# psoc4hvpaspm10 register map
Vendor: Infineon Technologies; Series: PSOC4HVPASPM10; File version: 1.0
CPU: CM0PLUS r0p1, little endian, MPU, no FPU, VTOR, 2 interrupt priority bits, 32 interrupts
Registers are 32-bit, read-write, reset 0x0 unless marked. A register's access mark holds for its fields unless they carry their own. Offsets are from the block's base; [hi:lo] are bit positions; lines under a group give offsets from that group; 'fields as' and 'values as' point back to an identical list; <NAME> marks a mode.

## SRSSHV — System Resources High Voltage Subsystem
Base 0x40030000
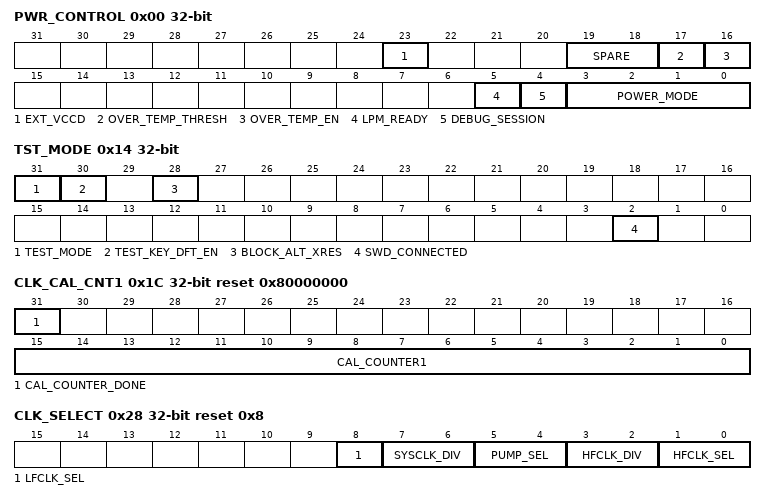
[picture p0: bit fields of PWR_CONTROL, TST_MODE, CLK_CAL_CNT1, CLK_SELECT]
0x00 PWR_CONTROL — Power Mode Control (Lock Protected)
  [23] EXT_VCCD — Always write 0 except as noted below. PSoC4-S0 and Streetfighter CapSense products may set this bit if Vccd is provided externally (on Vccd pin). Setting this bit turns off the active regulator and will lead to system reset (BOD) unless both Vddd and Vccd pins are supplied externally. This register field reset with hard reset (power related, XRES, WDT).
  [19:18] SPARE ro — Spare AHB readback bits that are hooked to PWR_PWRSYS_TRIM1.SPARE_TRIM[1:0] through spare logic equivalent to bitwise inversion. Engineering only, should always be set to default.
  [17] OVER_TEMP_THRESH — Over-temperature threshold. 0: TEMP_HIGH condition occurs between 110C and 145C. 1: TEMP_HIGH condition occurs between 50C and 90C (used for testing).
  [16] OVER_TEMP_EN — Enables the die over temperature sensor. Must be enabled when using the TEMP_HIGH interrupt.
  [5] LPM_READY ro — Indicates whether the low power mode regulator is ready to enter DeepSleep mode. 0: If DeepSleep mode is requested, device will enter SLEEP mode. When low power regulators are ready, device will automatically enter the originally requested mode. 1: Normal operation. DeepSleep works as described.
  [4] DEBUG_SESSION ro — Indicates whether a debug session is active (CDBGPWRUPREQ signal is 1)
    0=NO_SESSION (No debug session active); 1=SESSION_ACTIVE (Debug session is active)
  [3:0] POWER_MODE ro — Current power mode of the device. Note that this field cannot be read in all power modes on actual silicon.
    0=RESET (RESET state); 1=ACTIVE (ACTIVE state); 2=SLEEP (SLEEP state); 3=DEEP_SLEEP (DEEP_SLEEP state)
0x04 PWR_KEY_DELAY reset 0xF8 — Power System Key&Delay Register (Lock Protected)
  [9:0] WAKEUP_HOLDOFF — Delay to wait for references to settle on wakeup from DeepSleep. BOD is ignored and system does not resume until this delay expires. Note that the same delay on POR is hard-coded. The default assumes the output of the predivider is 48MHz + 3 percent. Firmware may scale this setting according to the fastest actual clock frequency that can occur when waking from DeepSleep.
0x14 TST_MODE — Test Mode Control Register
  [31] TEST_MODE
  [30] TEST_KEY_DFT_EN ro
  [28] BLOCK_ALT_XRES — Relevant only for parts that have the alternate XRES mechanism of overloading a GPIO pin temporarily as alternate XRES during test. When set, this bit blocks the alternate XRES function, such that the pin can be used for normal I/O or for ddft/adft observation. This register field resets with hard reset (power related, XRES, WDT)
  [2] SWD_CONNECTED ro
0x1C CLK_CAL_CNT1 reset 0x80000000 — Clock Calibration Counter 1
  [31] CAL_COUNTER_DONE ro — Status bit indicating that the internal counter #1 is finished counting and CLK_CAL_CNT2.COUNTER stopped counting up
  [15:0] CAL_COUNTER1 — Down-counter clocked on DFT output #0 (see CLK_DFT_SELECT). This register always reads as zero. Counting starts internally when this register is written with a nonzero value. CAL_COUNTER_DONE goes immediately low to indicate that the counter has started and will be asserted when the counters are done. Do not write this field unless CAL_COUNTER_DONE==1. Both clocks must be running or the measurement will not complete. A stalled counter can be recovered by selecting valid clocks, waiting until the measurement completes, and discarding the first result. CAL_COUNTER1 should always be > 1. Due to internal clock synchronization CAL_COUNTER1 should be at least 5 times the 1/F_cnt2.
0x20 CLK_CAL_CNT2 ro — Clock Calibration Counter 2
  [15:0] CAL_COUNTER2 — Up-counter clocked on DFT output #1 (see CLK_DFT_SELECT). When CLK_CAL_CNT1.CAL_COUNTER_DONE==1, the counter is stopped and can be read by SW. Do not read this value unless CAL_COUNTER_DONE==1. The expected final value is related to the ratio of clock frequencies used for the two counters and the value loaded into counter 1: CLK_CAL_CNT2.CAL_COUNTER2=(F_cnt2/F_cnt1)*(CLK_CAL_CNT1.CAL_COUNTER1)
0x28 CLK_SELECT reset 0x8 — Clock Select Register (Lock Protected)
  [8] LFCLK_SEL — Low Frequency Clock Select. Selecting a clock source that is not enabled will result in undefined behavior. If a clock source is disabled while selected, then the clock merely stops to all sources that receive it. In such a scenario, the disabled clock must be re-enabled, prior to switching FROM this clock source. Writes to this field are ignored unless the WDT is unlocked using WDT_LOCK register. It takes about 3 cycles of the new selected clock to switch away from the old clock to the new clock. Do not disable the original clock during this time. This register field resets with hard reset (power related, XRES, WDT).
    0=ILO (ILO - Internal Low Frequency Oscillator); 1=PILO (PILO - Precision Internal Low Frequency Oscillator. Only if PILO_PRESENT=1)
  [7:6] SYSCLK_DIV — Select clk_sys prescaler value.
    0=NO_DIV (clk_sys= clk_hf/1); 1=DIV_BY_2 (clk_sys= clk_hf/2); 2=DIV_BY_4 (clk_sys= clk_hf/4); 3=DIV_BY_8 (clk_sys= clk_hf/8)
  [5:4] PUMP_SEL — Selects clock source for charge pump clock. This clock is not guaranteed to be glitch free when changing any of its sources or settings.
    0=GND (No clock, connect to gnd); 1=IMO (Use main IMO output); 2=HFCLK (Use clk_hf (using selected source after predivider but before prescaler))
  [3:2] HFCLK_DIV — Selects clk_hf predivider value. It will take 3-4 clock cycles to switch to the new predivder value
    0=NO_DIV (Transparent mode, feed through selected clock source w/o dividing.); 1=DIV_BY_2 (Divide selected clock source by 2); 2=DIV_BY_4 (Divide selected clock source by 4); 3=DIV_BY_8 (Divide selected clock source by 8)
  [1:0] HFCLK_SEL — Selects a source for clk_hf and dsi_in[0]. Note that not all products support all clock sources. Selecting a clock source that is not supported or enabled will result in undefined behavior. It takes about 3 cycles of the new selected clock to switch away from the old clock to the new clock. Do not disable the original clock during this time.
    0=IMO (IMO - Internal R/C Oscillator); 1=EXTCLK (EXTCLK - External Clock Pin); 2=ECO (ECO - External-Crystal Oscillator or PLL subsystem output); 3=HPOSC (HPOSC - High Precision Oscillator. Only if HPOSC_PRESENT=1)
0x2C CLK_ILO_CONFIG reset 0x80000000 — ILO Configuration (Lock Protected)
  [31] ENABLE — Master enable for ILO oscillator. Clearing this bit will disable the ILO. Do not disable this clock if the CLK_LF uses it clock the source. Writes to this field are ignored when LFCLK_SEL is using this clock as the source and WDT is locked using WDT_LOCK register. This register resets when there is power related reset POR/XRES/BOD/OVD/WDT
0x30 CLK_IMO_CONFIG reset 0x80000000 — IMO Configuration (Lock Protected)
  [31] ENABLE — Master enable for IMO oscillator. Clearing this bit will disable the IMO. Don't do this if the system is running off it.
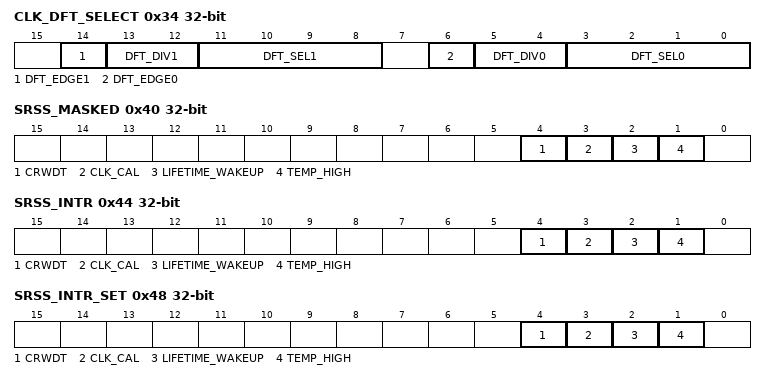
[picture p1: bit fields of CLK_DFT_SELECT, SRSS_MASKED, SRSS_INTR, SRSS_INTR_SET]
0x34 CLK_DFT_SELECT — Clock DFT Mode Selection Register
  [14] DFT_EDGE1 — Edge sensitivity for pre-divider (only relevant when DIV0>0).
    0=POSEDGE (Use posedge for divider); 1=NEGEDGE (Use negedge for divider)
  [13:12] DFT_DIV1 — Calibration Counter #2 pre-divider
    0=NO_DIV (Direct Output); 1=DIV_BY_2 (Divide by 2); 2=DIV_BY_4 (Divide by 4); 3=DIV_BY_8 (Divide by 8)
  [11:8] DFT_SEL1 — Select clock for Calibration Counter #2
    0=NC (Disabled - output is 0); 1=ILO (clk_ilo: ILO output); 2=IMO (clk_imo: IMO primary output); 3=ECO (clk_eco: ECO output); 4=EXTCLK (clk_ext: external clock input); 5=HFCLK (clk_hf: root of the high-speed clock tree); 6=LFCLK (clk_lf: root of the low-speed clock tree); 7=SYSCLK (clk_sys: root of the CPU/AHB clock tree (gated version of clk_hf)); 8=PUMPCLK (clk_pump: clock provided to charge pumps in FLASH and PA); 9=SLPCTRLCLK (clk_slpctrl: clock provided to Sleep Controller); 10=HPOSC (clk_hposc: HPOSC output. Applicable only if HPOSC_PRESENT=1); 11=PILO (clk_pilo: PILO output. Applicable only if PILO_PRESENT=1); 12=ILO_EN (clk_ilo: enable. Use for startup time measurements. Use only with DFT_DIV0.NO_DIV); 13=IMO_EN (clk_imo: enable. Use for startup time measurements. Use only with DFT_DIV0.NO_DIV); 14=HPOSC_EN (clk_hposc: enable. If HPOSC_PRESENT=1, Use for startup time measurements. Use only with DFT_DIV0.NO_DIV); 15=PILO_EN (clk_pilo: enable. If PILO_PRESENT=1, Use for startup time measurements. Use only with DFT_DIV0.NO_DIV)
  [6] DFT_EDGE0 — Edge sensitivity for pre-divider (only relevant when DIV0>0).
    values as DFT_EDGE1
  [5:4] DFT_DIV0 — Calibration Counter #1 pre-divider
    values as DFT_DIV1
  [3:0] DFT_SEL0 — Select clock for Calibration Counter #1
    values as DFT_SEL1
0x40 SRSS_MASKED ro — SRSS Interrupt Masked Register
  [4] CRWDT — Logical and of corresponding request and mask bits.
  [3] CLK_CAL — Logical and of corresponding request and mask bits.
  [2] LIFETIME_WAKEUP — Logical and of corresponding request and mask bits.
  [1] TEMP_HIGH — Logical and of corresponding request and mask bits.
0x44 SRSS_INTR — SRSS Interrupt Register
  [4] CRWDT write-1-clears — Interrupt from CRWDT. This bit is set by the CRWDT when enabled by CRWDT_CONFIG.
  [3] CLK_CAL write-1-clears — Clock calibration counter is done. This field is reset during DeepSleep mode.
  [2] LIFETIME_WAKEUP write-1-clears — Wakeup Interrupt from LIFETIME Counter. This bit is set when LIFETIME_COUNTER ==LIFETIME_WAKEUP. This is a DeepSleep Interrupt. The interrupt source will reset only with hard reset (power related, XRES, WDT).
  [1] TEMP_HIGH write-1-clears — Regulator over-temp interrupt. This interrupt can occur when a short circuit exists on the vccd pin or when extreme loads are applied on IO-cells causing the die to overheat. Firmware is encourage to shutdown all IO cells and then go to DeepSleep mode when this interrupt occurs if protection against such conditions is desired.
0x48 SRSS_INTR_SET — SRSS Interrupt Set Register
  [4] CRWDT write-1-sets — Set interrupt for Challenge/Response Interrupt. Reads back same as SRSS_INTR.CRWDT.
  [3] CLK_CAL write-1-sets — Set interrupt for clock calibration counter done. This field is reset during DeepSleep mode. Reads back same as SRSS_INTR.CLK_CAL.
  [2] LIFETIME_WAKEUP write-1-sets — Writing 1 to this bit internally sets the LIFETIME_WAKEUP interrupt. Reads back same as SRSS_INTR.LIFETIME_WAKEUP. The interrupt source will reset only with hard reset (power related, XRES, WDT).
  [1] TEMP_HIGH write-1-sets — Writing 1 to this bit internally sets the overtemp interrupt. This can be observed by reading SRSS_INTR.TEMP_HIGH. This bit always reads back as zero.
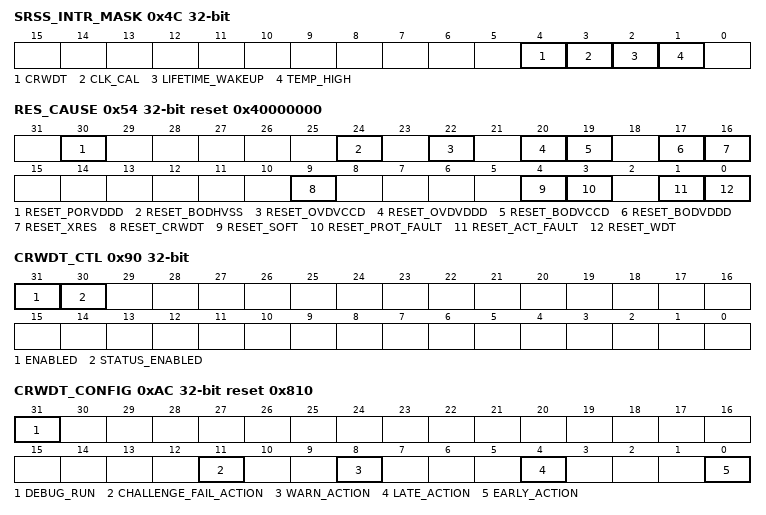
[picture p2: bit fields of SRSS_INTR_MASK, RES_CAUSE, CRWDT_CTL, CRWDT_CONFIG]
0x4C SRSS_INTR_MASK — SRSS Interrupt Mask Register
  [4] CRWDT — Mask for CRWDT interrupt
  [3] CLK_CAL — Mask for clock calibration done
  [2] LIFETIME_WAKEUP — Mask for lifetime counter
  [1] TEMP_HIGH — Masks REG_OVERTEMP interrupt
0x54 RES_CAUSE reset 0x40000000 — Reset Cause Observation Register
  [30] RESET_PORVDDD write-1-clears — Indicator that a POR occurred. This is a high-voltage cause bit, and hardware clears the other bits when this one is set. It does not block further recording of other high-voltage causes.
  [24] RESET_BODHVSS write-1-clears — Internal VDDD supply crossed brown-out limit. Note that this cause will only be observable as long as the VDDD supply does not go below the POR (power on reset) detection limit. Below this limit it is not possible to reliably retain information in the device. This is a high-voltage cause bit that blocks recording of other high-voltage cause bits, except RESET_PORVDDD and RESET_XRES. Hardware clears this bit during POR. This detector is a backup detector in the high voltage sub-system that is on even in deep sleep. This detector is used for engineering debug purposes only.
  [22] RESET_OVDVCCD write-1-clears — Overvoltage detection on the internal core VCCD supply. This is a high-voltage cause bit that blocks recording of other high-voltage cause bits, except RESET_PORVDDD and RESET_XRES. Hardware clears this bit during POR.
  [20] RESET_OVDVDDD write-1-clears — Overvoltage detection on the external VDDD supply. This is a high-voltage cause bit that blocks recording of other high-voltage cause bits, except RESET_PORVDDD and RESET_XRES. Hardware clears this bit during POR.
  [19] RESET_BODVCCD write-1-clears — Internal VCCD core supply crossed the brown-out limit. Note that this detector will detect gross issues with the internal core supply, but may not catch all brown-out conditions. Functional and timing supervision (CSV, WDT) is provided to create fully failsafe internal crash detection. This is a high-voltage cause bit that blocks recording of other high-voltage cause bits, except RESET_PORVDDD and RESET_XRES. Hardware clears this bit during POR.
  [17] RESET_BODVDDD write-1-clears — Internal VDDD supply crossed brown-out limit. Note that this cause will only be observable as long as the VDDD supply does not go below the POR (power on reset) detection limit. Below this limit it is not possible to reliably retain information in the device. This is a high-voltage cause bit that blocks recording of other high-voltage cause bits, except RESET_PORVDDD and RESET_XRES. Hardware clears this bit during POR.
  [16] RESET_XRES write-1-clears — External XRES pin was asserted. This is a high-voltage cause bit that blocks recording of other high-voltage cause bits, except RESET_PORVDDD. Hardware clears this bit during POR. This bit is not blocked by other HV cause bits.
  [9] RESET_CRWDT write-1-clears — Challenge/Response Watchdog reset. This is a low-voltage cause bit that hardware clears when the low-voltage supply is initialized (see comments above).
  [4] RESET_SOFT write-1-clears — Cortex-M0 requested a system reset through it's SYSRESETREQ. This can be done via a debugger probe or in firmware.
  [3] RESET_PROT_FAULT write-1-clears — A protection violation occurred that requires a RESET. This includes, but is not limited to, hitting a debug breakpoint while in Privileged Mode.
  [1] RESET_ACT_FAULT write-1-clears — Reset caused by the Fault Infrastructure. This is a low-voltage cause bit that hardware clears when the low-voltage supply is initialized (see comments above).
  [0] RESET_WDT write-1-clears — A WatchDog Timer reset has occurred since last power cycle. This is a high-voltage cause detection, this bit blocks recording of other high-voltage cause bits, except RESET_PORVDDD and XRES. Hardware clears this bit during POR. This bit is not blocked by other HV cause bits.
0x80 REG_PROT reset 0xF08169E7 — Register Protection
  [31:0] MAGIC — Setting this register to the value 0xf08169e7 unlocks access to Lock Protected Registers. These registers can not be written to unless this value has been written into this register. Writing a value OTHER than the magic key will disable access to the registers. The register POR value is set to 'unlock' the register access. The registers locked are PWR_CONTROL, PWR_KEY_DELAY, CLK_SELECT, CLK_ILO_CONFIG, CLK_IMO_CONFIG, CRWDT_CTL, CRWDT_EARLY, PWR_SSV_CTL, CRWDT_WARN, CRWDT_LATE, LIFETIME_CTL,HPOSC_CTL(if HPOSC_PRESENT=1), PILO_CTL(if PILO_PRESENT=1), and all trim registers
0x90 CRWDT_CTL — Challenge Response WatchDog Control (Lock Protected)
  [31] ENABLED — When set to '1' enables Challenge/Response WatchDog Timer to Count. Will require 2 clk_lf cycles to take effect.
  [30] STATUS_ENABLED ro — Indicates actual state of CRWDT enable. May lag ENABLED by up to one clk_lf cycles.
0x94 CRWDT_CHALLENGE ro reset 0xFF — Challenge Response WatchDog Challenge Value
  [7:0] CHALLENGE — Challenge/Response WatchDog Challenge value. Implements the LFSR CCRC8-AutoSar using the polynomial x^8+x^5+x^3+x^2+x+1. The next value in the LFSR sequence is used to compare against the value subsequently written to the CRWDT_RESPONSE register. Incremented by write to CRWDT_RESPONSE to LFSR value next in the LFSR sequence after the value written to CRWDT_RESPONSE. Also incremented each time this register before a response is written to CRWDT_RESPONSE.
0x98 CRWDT_RESPONSE reset 0xFF — Challenge Response WatchDog Response Value
  [7:0] RESPONSE — Challenge/Response WatchDog Response value. Value is compared against the expected next value in the LFSR sequence following the value obtained from CRWDT_CHALLENGE. If the values match, the CRWDT_UPCNT resets. If the values miscompare, the action selected by CRWDT_CONFIG.CHALLENGE_FAIL_ACTION occurs.
0x9C CRWDT_UPCNT ro — Challenge Response WatchDog Up Counter
  [23:0] UPCNT — Challenge/Response WatchDog Up Counter. The counter upcounts upon every clk_lf occurrence when enabled. If a match occurs between CRWDT_CHALLENGE and CRWDT_RESPONSE, the counter resets. If there is a mismatch, the action is taken selected by CRWDT_CONFIG.CHALLENGE_FAIL_ACTION. The counter will also reset when CRWDT_UPCNT=CRWDT_LATE. CRWDT_CTL.ENABLED=0 - Counter reset CRWDT_CTL.ENABLED=1 - Counter Increments
0xA0 CRWDT_EARLY — Challenge Response WatchDog Early Limit (Lock Protected)
  [23:0] EARLY — Challenge/Response Early Value will cause the action selected by CRWDT_CONFIG.EARLY_ACTION if CRWDT_UPCNT < CRWDT_EARLY and there is a CRWDT_CHALLENGE/CRWDT_RESPONSE match. Writes to this register are ignored when CRWDT_CTL.ENABLED<>0.
0xA4 CRWDT_WARN — Challenge Response WatchDog Warning Limit (Lock Protected)
  [23:0] WARNING — Challenge/Response Warning Value will cause the action selected by CRWDT_CONFIGWARN_ACTION if CRWDT_UPCNT>CRWDT_WARN and there is a CRWDT_CHALLENGE/CRWDT_RESPONSE match. Writes to this register are ignored when CRWDT_CTL.ENABLED<>0.
0xA8 CRWDT_LATE — Challenge Response WatchDog Late Limit (Lock Protected)
  [23:0] LATE — Challenge/Response Late Value will cause action selected by CRWDT_CONFIG.LATE_ACTION if CRWDT_UPCNT = CRWDT_LATE. Writes to this register are ignored when CRWDT_CTL.ENABLED<>0.
0xAC CRWDT_CONFIG reset 0x810 — Challenge Response WatchDog Configuration
  [31] DEBUG_RUN — Pauses/runs this counter while a debugger is connected. Other behaviors are unchanged during debugging, including service, configuration updates and enable/disable. Note it may take up to two clk_lf cycles for the counter to pause and another two cycles to unpause, due to internal synchronization. If the debugger is connected for at least two clk_lf cycles, the EARLY_ACTION is ignored until after the first service after the debugger is disconnected. This prevents an unintentional trigger of the EARLY_ACTION before the firmware realigns the servicing period. After the first service, EARLY_ACTION behaves as configured. If the debugger is disconnected before two clk_lf cycles, the EARLY_ACTION may or may not be ignored. 0: When debugger connected, counter pauses incrementing. 1: When debugger connected, counter increments normally, but reset generation is blocked. Writes to this register are ignored when CRWDT_CTL.ENABLED<>0.
  [11] CHALLENGE_FAIL_ACTION — Action taken when a failed response occurs, i.e. the expected LFSR value is different than the expected value. Writes to this register are ignored when CRWDT_CTL.ENABLED<>0.
    0=NOTHING (Do nothing); 1=RESET (Trigger a reset)
  [8] WARN_ACTION — Action taken if this watchdog when the proper response is written to CRWDT_RESPONSE and CRWDT_UPCNT reaches CRWDT_WARN and CRWDT_UPCNT<CRWDT_LATE. WARN_ACTION is ignored (i.e. treated as NOTHING) when a debugger is connected. For CRWDT_WARN == CRWDT_UPCNT && CRWDT_LATE > CRWDT_UPCNT: The action is triggered on same edge as when it meets this condition. For CRWDT_WARN <CRWDT_UPCNT: No action is triggered. Writes to this register are ignored when CRWDT_CTL.ENABLED<>0.
    0=NOTHING (Do nothing); 1=FAULT_AND_INT (Trigger a Fault and interrupt)
  [4] LATE_ACTION — Action taken if this watchdog is not serviced before CRWDT_LATE s reached. The counter resets CRWDT_UPCNT when CRWDT_LATE is reached, regardless of CRWDT_CONFIG.LATE_ACTION setting. LATE_ACTION is ignored (i.e. treated as NOTHING) when a debugger is connected. For CRWDT_LATE == CRWDT_UPCNT: The action is triggered on same edge as when it meets this condition. For CRWDT_LATE > CRWDT_UPCNT: No action is taken Writes to this register are ignored when CRWDT_CTL.ENABLED<>0.
    0=NOTHING (Do nothing); 1=FAULT_RESET (Trigger a fault. Further, trigger a system-wide reset if the CRWDT is not disabled within 6 clk_lf cycles.)
  [0] EARLY_ACTION — Action taken if this watchdog when the proper response is written to CRWDT_RESPONSE before CRWDT_UPCNT reaches CRWDT_EARLY. EARLY_ACTION is ignored (i.e. treated as NOTHING) when a debugger is connected. For CRWDT_EARLY > CRWDT_UPCNT: The action is triggered on same edge as when it meets this condition. For CRWDT_EARLY <= CRWDT_UPCNT: No action is triggered. Writes to this register are ignored when CRWDT_CTL.ENABLED<>0.
    values as WARN_ACTION
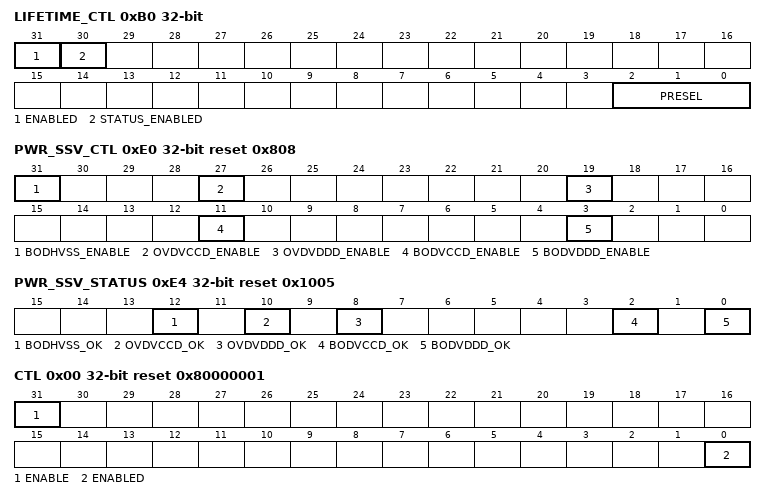
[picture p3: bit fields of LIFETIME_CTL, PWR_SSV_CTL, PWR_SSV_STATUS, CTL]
0xB0 LIFETIME_CTL — Liftetime Counter Control (Lock Protected)
  [31] ENABLED — When set to '1' enables LIFETIME_COUNTER to increment. Due to internal synchronization, may take up to one clk_lf cycles to take effect. The synchronization can be checked by waiting until ENABLED==STATUS_ENABLED whenever ENABLED is changed. When ENABLE changes from 1->0, the counter can be loaded with new COUNT value. Refer to LIFETIME_COUNTER.COUNT for details. User can enter DeepSleep without waiting for synchronization to complete (ENABLED==STATUS_ENABLED). This register bit only resets for XRES, POR, or a detected BOD.
  [30] STATUS_ENABLED ro — Indicates actual state of lifetime counter enable. May lag ENABLED by up to one clk_lf cycles.
  [2:0] PRESEL — Select Divide ratio for Preselector. Legal values are 0-4. Values 5, 6, and 7 yield the same result as PERSEL_DIV32. Do not change this setting when lifetime counter is enabled (LIFETIME_CTL.ENABLED=1). Due to internal synchronization, it takes about 1 LFCLK cycles to update the counters after a write to this register. This register bit only resets for XRES, POR, or a detected BOD.
    0=PRESEL_DIV2 (Divide CLK_LF by 2); 1=PRESEL_DIV4 (Divide CLK_LF by 4); 2=PRESEL_DIV8 (Divide CLK_LF by 8); 3=PRESEL_DIV16 (Divide CLK_LF by 16); 4=PRESEL_DIV32 (Divide CLK_LF by 32)
0xB4 LIFETIME_WAKEUP reset 0xFFFFFFFF — Lifetime Wakeup Value
  [31:0] WAKEUP — Compare the WAKEUP value against LIFETIME_COUNTER. If they are equal interrupt_wakeup to set. Due to internal synchronization, it may take up to 1 LFCLK cycles to update the counters after a write to this register. This register bit only resets for XRES, POR, or a detected BOD.
0xB8 LIFETIME_COUNTER — Lifetime Counter Current Value
  [31:0] COUNT — Lifetime Counter which clocks on the output of the CLK_LF PreScalar output controlled by LIFETIME_CTL.PRESEL. The counter doesn't increment unless LIFETIME_CTL.STATUS_ENABLED =1. FW is responsible for initializing this value after reset and maintaining the running value. SW writes will be ignored when LIFETIME_CTL.ENABLED=1. The counter needs to be disabled one LFCLK cycle (or LIFETIME_CTL.STATUS_ENABLED=0) for the internal synchronization of this field to take place. This register bit only resets for XRES, POR, or a detected BOD.
0xE0 PWR_SSV_CTL reset 0x808 — Supply Supervisory Control Register (Lock Protected)
  [31] BODHVSS_ENABLE — Enable for BOD on vddd from HVSS. This gives BOD robustness during DeepSleep. FW should enable during boot-up and keep it enabled.
  [27] OVDVCCD_ENABLE — Enable for OVD on vccd. FW should enable this after the OVD trims are set during boot-up and keep it enabled.
  [19] OVDVDDD_ENABLE — Enable for OVD on vddd. FW should enable this after the OVD trims are set during boot-up and keep it enabled.
  [11] BODVCCD_ENABLE — Enable for BOD on vccd. This cannot be disabled during normal operation.
  [3] BODVDDD_ENABLE — Enable for BOD on vddd. This cannot be disabled during normal operation.
0xE4 PWR_SSV_STATUS ro reset 0x1005 — Supply Supervision Status Register
  [12] BODHVSS_OK — BODHVSS indicates vddd is ok. This will always read 1, because a detected brownout will reset the chip.
  [10] OVDVCCD_OK — OVD indicates vccd is ok. After OVDVCCD is enabled it will always read 1, because a detected over-over-voltage condition will reset the chip.
  [8] OVDVDDD_OK — OVD indicates vddd is ok. After OVDVDDD is enabled it will always read 1, because a detected over-voltage condition will reset the chip.
  [2] BODVCCD_OK — BOD indicates vccd is ok. This will always read 1, because a detected brownout will reset the chip.
  [0] BODVDDD_OK — BOD indicates vddd is ok. This will always read 1, because a detected brownout will reset the chip.
0x100 WDT group — Watchdog Timer
  0x00 CTL reset 0x80000001 — WDT Control Register
    [31] ENABLE — Enable watchdog. May take up to three clk_lf cycles to take effect. When ENABLE changes from 1->0, the counter is cleared. Do not enter DeepSleep if ENABLE<>ENABLED. This can be done by waiting until ENABLE==ENABLED whenever ENABLE is changed. 0: Counter is disabled (not clocked). 1: Counter is enabled (counting up)
    [0] ENABLED ro — Indicates actual state of watchdog. May lag ENABLE by up to three clk_lf cycles.
  0x04 LOWER_LIMIT — WDT Lower Limit Register
    [31:0] LOWER_LIMIT — Lower limit for watchdog. See LOWER_ACTION.
  0x08 UPPER_LIMIT reset 0x8000 — WDT Upper Limit Register
    [31:0] UPPER_LIMIT — Upper limit for watchdog. See UPPER_ACTION.
  0x0C WARN_LIMIT — WDT Warn Limit Register
    [31:0] WARN_LIMIT — Warn limit for watchdog. See WARN_ACTION.
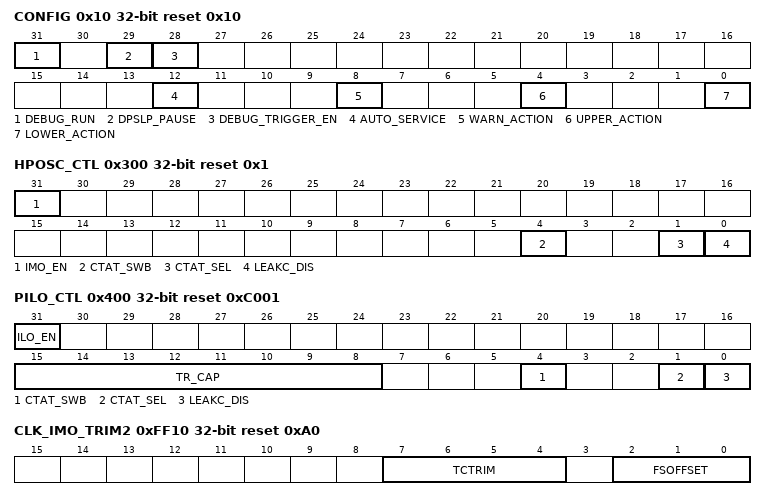
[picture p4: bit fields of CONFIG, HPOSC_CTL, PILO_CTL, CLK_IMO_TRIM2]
  0x10 CONFIG reset 0x10 — WDT Configuration Register
    [31] DEBUG_RUN — Pauses/runs this counter while a debugger is connected. Other behaviors are unchanged during debugging, including service, configuration updates and enable/disable. Note it may take up to two clk_lf cycles for the counter to pause and another two cycles to unpause, due to internal synchronization. If the debugger is connected for at least two clk_lf cycles, the LOWER_ACTION is ignored until after the first service after the debugger is disconnected. This prevents an unintentional trigger of the LOWER_ACTION before the firmware realigns the servicing period. After the first service, LOWER_ACTION behaves as configured. If the debugger is disconnected before two clk_lf cycles, the LOWER_ACTION may or may not be ignored. 0: When debugger connected, counter pauses incrementing as configured in DEBUG_TRIGGER_EN. 1: When debugger connected, counter increments normally, but reset generation is blocked.
    [29] DPSLP_PAUSE — Pauses/runs this counter when the system is in DeepSleep. Note it may take up to two clk_lf cycles for the counter to pause, due to internal synchronization. During DeepSleep wakeup, the pause request is removed when clk_hf starts clocking, and then it may take up to two clk_lf cycles for the counter to start. After wakeup, the LOWER_ACTION is ignored until after the first service. This prevents an unintentional trigger of the LOWER_ACTION before the firmware realigns the servicing period. After the first service, LOWER_ACTION behaves as configured. 0: Counter behaves normally during DeepSleep. 1: Counter pauses during DeepSleep.
    [28] DEBUG_TRIGGER_EN — Enables the trigger input for WDT to pause the counter during debug mode. To pause at a breakpoint while debugging, configure the trigger matrix to connect the related CPU halted signal to the trigger input for this WDT, and then set this bit. It takes up to two clk_lf cycles for the trigger signal to be processed. Triggers that are less than two clk_lf cycles may be missed. Synchronization error can accumulate each time it is halted. 0: Pauses the counter whenever a debug probe is connected. 1: Pauses the counter whenever a debug probe is connected and the trigger input is high.
    [12] AUTO_SERVICE — Automatically service when the count value reaches WARN_LIMIT. This allows creation of a periodic interrupt if this counter is not needed as a watchdog. This field is ignored when LOWER_ACTION<>NOTHING or when UPPER_ACTION<>NOTHING.
    [8] WARN_ACTION — Action taken when the count value reaches WARN_LIMIT. The minimum setting to achieve a periodic interrupt is WARN_LIMIT==1. A setting of zero will trigger once but not periodically. For WARN_LIMIT >= 2: The action is triggered on same edge when it meets this condition. For WARN_LIMIT < 2 : The action may take up to one extra clk_lf cycle to trigger.
      0=NOTHING (Do nothing); 1=INT (Trigger an interrupt.)
    [4] UPPER_ACTION — Action taken if this watchdog is not serviced before UPPER_LIMIT is reached. The counter stops counting when UPPER_LIMIT is reached, regardless of UPPER_ACTION setting. UPPER_ACTION is ignored (i.e. treated as NOTHING) when a debugger is connected. For UPPER_LIMIT >= 2: The action is triggered on same edge when it meets this condition. For UPPER_LIMIT < 2: The action may take up to one extra clk_lf cycle to trigger.
      0=NOTHING (Do nothing); 1=RESET (Trigger a reset.)
    [0] LOWER_ACTION — Action taken if this watchdog is serviced before LOWER_LIMIT is reached. LOWER_ACTION is ignored (i.e. treated as NOTHING) when a debugger is connected and/or when the chip is in DeepSleep modes. For LOWER_LIMIT >= 1: The action is triggered on same edge when it meets this condition. For LOWER_LIMIT == 0: No action is triggered.
      0=NOTHING (Do nothing); 1=RESET (Trigger a reset.)
  0x14 CNT — WDT Count Register
    [31:0] CNT — Current value of subcounter for this WDT. This field may lag the actual count value by up to one clk_lf cycle, due to internal synchronization. When this subcounter is disabled and unlocked, the count value can be written for verification and debugging purposes. Software writes are always ignored when the subcounter is enabled.
  0x40 LOCK reset 0x3 — WDT Lock register
    [1:0] WDT_LOCK — Prohibits writing control and configuration registers related to this WDT when not equal 0 (as specified in the other register descriptions). Requires at least two different writes to unlock. Note that this field is 2 bits to force multiple writes only. This register also locks the clk_lf settings.
      0=NO_CHG (No effect); 1=CLR0 (Clears bit 0); 2=CLR1 (Clears bit 1); 3=SET01 (Sets both bits 0 and 1)
  0x44 SERVICE — WDT Service register
    [0] SERVICE write-1-sets — Services the watchdog. This resets the count value to zero. This may take up to three clk_lf cycle to take effect. Hardware clears this bit, after necessary synchronization. To ensure a pending SERVICE write is reflected, firmware should wait until this bit reads low before attempting to write SERVICE=1. If WDT is disabled, SERVICE will not trigger a LOWER_ACTION and will not clear a preloaded count value.
  0x50 INTR — WDT Interrupt Register
    [0] WDT write-1-clears — WDT Interrupt Request. This bit is set as configured by WDT action and limits. Due to internal synchronization, it takes up to 8 SYSCLK cycles to update after a W1C or reading this register and during this time AHB bus is stalled.
  0x54 INTR_SET — WDT Interrupt Set Register
    [0] WDT write-1-sets — Set interrupt. Due to internal synchronization, it takes up to 8 SYSCLK cycles to update after a W1S or reading from this register and during this time AHB bus is stalled. Reads back same as WDT_B.INTR.WDT
  0x58 INTR_MASK — WDT Interrupt Mask Register
    [0] WDT — Mask for watchdog timer. Clearing this bit will not forward the interrupt to the CPU.
  0x5C INTR_MASKED ro — WDT Interrupt Masked Register
    [0] WDT — Logical and of corresponding request and mask bits. Due to internal synchronization, it takes up to 8 SYSCLK cycles to read from this register. During this time AHB bus is stalled.
0x300 HPOSC_CTL reset 0x1 — High Precision Oscillator Control (Lock Protected)
  [31] IMO_EN — HPOSC enable. Setting this bit will enable the HPOSC and clearing this bit will disable the HPOSC. Don't disable this clock if the system is using this clock as the source.
  [4] CTAT_SWB — Selection control for internal CTAT generator. 0 - Auto Select (Fast start followed by low noise generator) 1 - Generator selected by CTAT_SEL
  [1] CTAT_SEL — CTAT generator selection, only valid when CTAT_SW = 1. 0 - Low noise type CTAT generator 1 - Fast start-up type CTAT generator
  [0] LEAKC_DIS
0x400 PILO_CTL reset 0xC001 — Precision Low Power Oscillator Control (Lock Protected)
  [31] ILO_EN — PILO enable. Setting this bit will enable the PILO and clearing this bit will disable it. Do not disable this clock prior to changing CLK_LF to use the PILO as a source. CLK_LF must be configured to use PILO as a source while the PILO clock is enabled prior to making such a change. Writes to this field are ignored when LFCLK_SEL is using this clock as the source and WDT is locked using WDT_LOCK register. Consequently, if CLK_LF is sourced by the PILO and the PILO is to be disabled, clear WDT_LOCK before-hand. This register field resets with hard reset (power related, XRES, WDT).
  [15:8] TR_CAP — PILO user temperature fine trim. This register field resets with hard reset (power related, XRES, WDT)..
  [4] CTAT_SWB — Selection control for internal CTAT generator. 0 - Auto Select (Fast start followed by low noise generator) 1 - Generator selected by CTAT_SEL
  [1] CTAT_SEL — CTAT generator selection, only valid when CTAT_SW = 1. 0 - Low noise type CTAT generator 1 - Fast start-up type CTAT generator
  [0] LEAKC_DIS
0xFF00 PWR_BG_TRIM1 reset 0xD — Bandgap Trim Register (Lock Protected)
  [5:0] REF_VTRIM — Trims the bandgap reference voltage output. Used to trim the VBG to the voltage where its temperature curvature is minimal. Bit [5] is unused within the bandgap block.
0xFF04 PWR_BG_TRIM2 reset 0x23 — Bandgap Trim Register (Lock Protected)
  [5:0] REF_ITRIM — Trims the bandgap reference current output. Used to trim the IBG to the voltage where its temperature curvature is minimal.
0xFF08 CLK_IMO_SELECT — IMO Frequency Select Register (Lock Protected)
  [2:0] FREQ — Select operating frequency
    0=24_MHZ (IMO runs at 24 MHz); 1=28_MHZ (IMO runs at 28 MHz); 2=32_MHZ (IMO runs at 32 MHz); 3=36_MHZ (IMO runs at 36 MHz); 4=40_MHZ (IMO runs at 40 MHz); 5=44_MHZ (IMO runs at 44 MHz); 6=48_MHZ (IMO runs at 48 MHz)
0xFF0C CLK_IMO_TRIM1 reset 0x6C — IMO Trim Register (Lock Protected)
  [7:0] OFFSET — Frequency trim bits. These bits are determined at manufacturing time for each FREQ setting (IMO_TRIM2) and stored in SFLASH. This field is hardware updated during USB osclock mode. This field is mapped to the most significant bits of the IMO trim imo_clk_trim[10:3]. The step size of 1 LSB on this field is nominally 160 kHz.
0xFF10 CLK_IMO_TRIM2 reset 0xA0 — IMO Trim Register (Lock Protected)
  [7:4] TCTRIM — IMO temperature compensation trim. These bits are determined at manufacturing time to adjust for temperature dependence. This bits are dependent on frequency and need to be changed using the Infineon provided frequency change algorithm.
  [2:0] FSOFFSET — Frequency trim bits. These bits are not trimmed during manufacturing and kept at 0 under normal operation. This field is hardware updated during USB osclock mode. This field is mapped to the least significant bits of the IMO trim imo_clk_trim[2:0]. The step size of 1 LSB on this field is nominally 20 kHz.
0xFF14 CLK_IMO_TRIM3 reset 0xF — IMO Trim Register (Lock Protected)
  [4:0] STEPSIZE — IMO trim stepsize bits. These bits are determined at manufacturing time to adjust for process variation. They are used to tune the stepsize of the FSOFFSET and OFFSET trims.
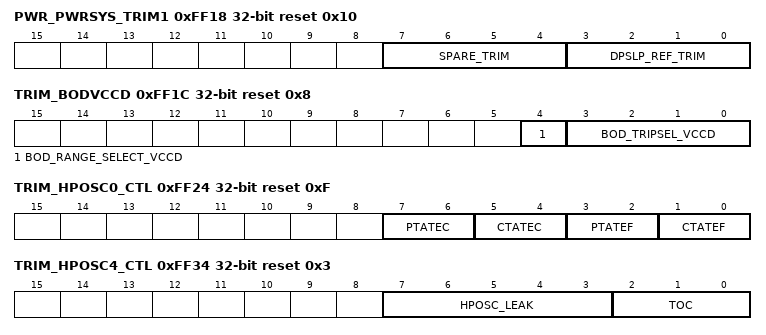
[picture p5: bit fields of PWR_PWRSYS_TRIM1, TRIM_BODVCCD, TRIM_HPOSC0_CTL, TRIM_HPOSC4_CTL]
0xFF18 PWR_PWRSYS_TRIM1 reset 0x10 — Power System Trim Register (Lock Protected)
  [7:4] SPARE_TRIM — Active-Reference temperature compensation trim (repurposed from spare bits). Bits [7:6] - trim the Active-Reference IREF temperature coefficient (TC). 00: TC = 0 (unchanged) 01: TC = +80ppm/C 10: TC = -80ppm/C 11: TC = -150ppm/C Bits [5:4] - trim the Active-Reference VREF temperature coefficient (TC). 00: TC = 0 (unchanged) 01: TC = -50ppm/C 10: TC = -80ppm/C 11: TC = +150ppm/C
  [3:0] DPSLP_REF_TRIM — Trims the DeepSleep reference that is used by the DeepSleep regulator and DeepSleep power comparator.
0xFF1C TRIM_BODVCCD reset 0x8 — Brown Out Detect Trim (VCCD) (Lock Protected)
  [4] BOD_RANGE_SELECT_VCCD — Range select between 1.6V Vs 1.69V nominal.
  [3:0] BOD_TRIPSEL_VCCD — BOD VCCD trim (production)
0xFF20 TRIM_OVDVCCD reset 0x7 — Over Voltage Detect Trim (VCCD) (Lock Protected)
  [3:0] OVD_TRIPSEL_VCCD — OVD VCCD trim (options)
0xFF24 TRIM_HPOSC0_CTL reset 0xF — High Precision Oscillator Trim Control 0 (Lock Protected)
  [7:6] PTATEC — Coarse trim for HPOSC PTAT current
  [5:4] CTATEC — Coarse trim for HPOSC CTAT current
  [3:2] PTATEF — Fine trim for HPOSC PTAT current
  [1:0] CTATEF — HPOSC frequency CTAT extra-fine trim
0xFF28 TRIM_HPOSC1_CTL reset 0xD — High Precision Oscillator Trim Control 1 (Lock Protected)
  [4:0] TCF — HPOSC temp-co fine trim
0xFF2C TRIM_HPOSC2_CTL reset 0xA4 — High Precision Oscillator Trim Control 2 (Lock Protected)
  [7:0] PTAT — HPOSC PTAT trim
0xFF30 TRIM_HPOSC3_CTL reset 0xB1 — High Precision Oscillator Trim Control 3 (Lock Protected)
  [7:0] CTAT — HPOSC CTAT trim
0xFF34 TRIM_HPOSC4_CTL reset 0x3 — High Precision Oscillator Trim Control 4 (Lock Protected)
  [7:3] HPOSC_LEAK — HPOSC leakage cancellation trim
  [2:0] TOC — HPOSC temp-co coarse trim
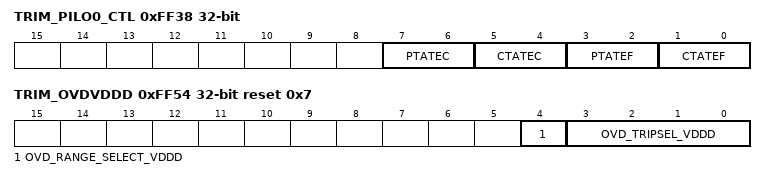
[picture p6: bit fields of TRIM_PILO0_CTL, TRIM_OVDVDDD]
0xFF38 TRIM_PILO0_CTL — Low Frequency Oscillator Trim Control 0 (Lock Protected)
  [7:6] PTATEC — PILO temperature PTATextra-coarse trim
  [5:4] CTATEC — PILO temperature CTAT extra-coarse trim
  [3:2] PTATEF — PILO frequency PTATextra-fine trim
  [1:0] CTATEF — PILO frequency CTAT extra-fine trim
0xFF3C TRIM_PILO1_CTL — Low Frequency Oscillator Trim Control 1 (Lock Protected)
  [4:0] TCF — PILO temp-co fine trim (MSB, bit 4, is not used)
0xFF40 TRIM_PILO2_CTL — Low Frequency Oscillator Trim Control 2 (Lock Protected)
  [7:0] PTAT — PILO frequency PTAT coarse trim
0xFF44 TRIM_PILO3_CTL — Low Frequency Oscillator Trim Control 3 (Lock Protected)
  [7:0] CTAT — PILO frequency CTAT coarse trim
0xFF48 TRIM_PILO4_CTL — Low Frequency Oscillator Trim Control 4 (Lock Protected)
  [3:0] TCC — PILO temperature coarse trim
0xFF4C TRIM_PILO5_CTL — Low Frequency Oscillator Trim Control 5 (Lock Protected)
  [4:0] PILO_TR_LEAK — PILO leakage cancellation trim
0xFF50 TRIM_BODVDDD reset 0x8 — Brown Out Detect Trim (VDDD) (Lock Protected)
  [3:0] BOD_TRIPSEL_VDDD — BOD VDDD trim (options)
0xFF54 TRIM_OVDVDDD reset 0x7 — Over Voltage Detect Trim (VDDD) (Lock Protected)
  [4] OVD_RANGE_SELECT_VDDD — Range select between 3.8V Vs 5.77V nominal.
  [3:0] OVD_TRIPSEL_VDDD — OVD VDDD trim (options)
